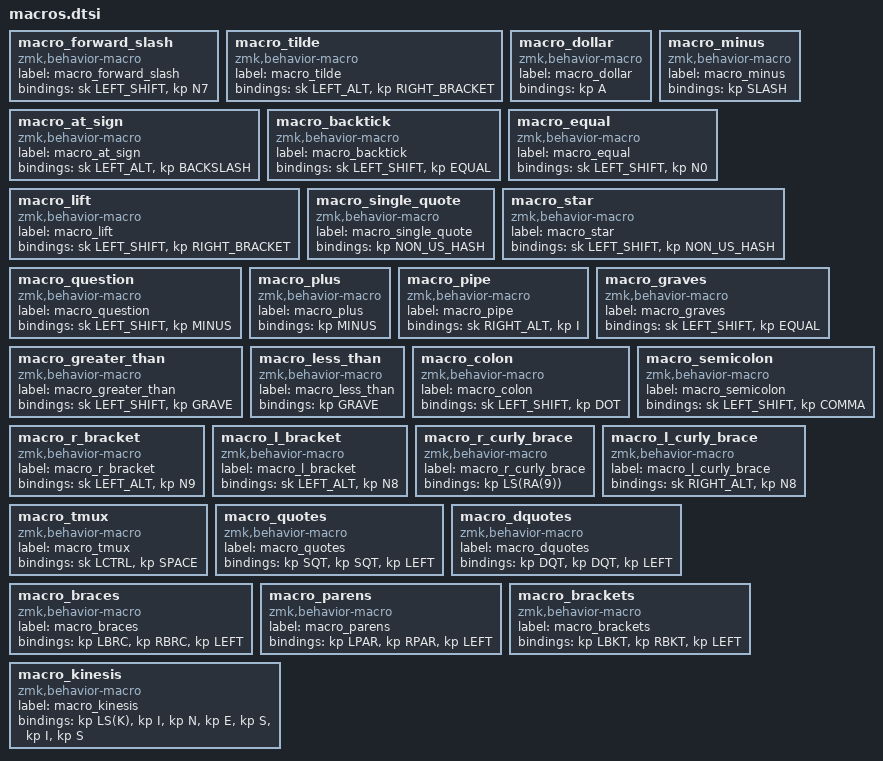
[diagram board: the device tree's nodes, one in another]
macro_forward_slash: macro_forward_slash{
compatible = "zmk,behavior-macro";
label = "macro_forward_slash";
#binding-cells = <0>;
bindings = <&sk LEFT_SHIFT>, <&kp N7>;
};
macro_tilde: macro_tilde{
compatible = "zmk,behavior-macro";
label = "macro_tilde";
#binding-cells = <0>;
bindings = <&sk LEFT_ALT>, <&kp RIGHT_BRACKET>;
};
macro_dollar: macro_dollar{
compatible = "zmk,behavior-macro";
label = "macro_dollar";
#binding-cells = <0>;
bindings = <&kp A>;
};
macro_minus: macro_minus{
compatible = "zmk,behavior-macro";
label = "macro_minus";
#binding-cells = <0>;
bindings = <&kp SLASH>;
};
macro_at_sign: macro_at_sign{
compatible = "zmk,behavior-macro";
label = "macro_at_sign";
#binding-cells = <0>;
bindings = <&sk LEFT_ALT>, <&kp BACKSLASH>;
};
macro_backtick: macro_backtick{
compatible = "zmk,behavior-macro";
label = "macro_backtick";
#binding-cells = <0>;
bindings = <&sk LEFT_SHIFT>, <&kp EQUAL>;
};
macro_equal: macro_equal{
compatible = "zmk,behavior-macro";
label = "macro_equal";
#binding-cells = <0>;
bindings = <&sk LEFT_SHIFT>, <&kp N0>;
};
macro_lift: macro_lift{
compatible = "zmk,behavior-macro";
label = "macro_lift";
#binding-cells = <0>;
bindings = <&sk LEFT_SHIFT>, <&kp RIGHT_BRACKET>;
};
macro_single_quote: macro_single_quote{
compatible = "zmk,behavior-macro";
label = "macro_single_quote";
#binding-cells = <0>;
bindings = <&kp NON_US_HASH>;
};
macro_star: macro_star{
compatible = "zmk,behavior-macro";
label = "macro_star";
#binding-cells = <0>;
bindings = <&sk LEFT_SHIFT>, <&kp NON_US_HASH>;
};
macro_question: macro_question{
compatible = "zmk,behavior-macro";
label = "macro_question";
#binding-cells = <0>;
bindings = <&sk LEFT_SHIFT>, <&kp MINUS>;
};
macro_plus: macro_plus{
compatible = "zmk,behavior-macro";
label = "macro_plus";
#binding-cells = <0>;
bindings = <&kp MINUS>;
};
macro_pipe: macro_pipe{
compatible = "zmk,behavior-macro";
label = "macro_pipe";
#binding-cells = <0>;
bindings = <&sk RIGHT_ALT>, <&kp I>;
};
macro_graves: macro_graves{
compatible = "zmk,behavior-macro";
label = "macro_graves";
#binding-cells = <0>;
bindings = <&sk LEFT_SHIFT>, <&kp EQUAL>;
};
macro_greater_than: macro_greater_than{
compatible = "zmk,behavior-macro";
label = "macro_greater_than";
#binding-cells = <0>;
bindings = <&sk LEFT_SHIFT>, <&kp GRAVE>;
};
macro_less_than: macro_less_than{
compatible = "zmk,behavior-macro";
label = "macro_less_than";
#binding-cells = <0>;
bindings = <&kp GRAVE>;
};
macro_colon: macro_colon{
compatible = "zmk,behavior-macro";
label = "macro_colon";
#binding-cells = <0>;
bindings = <&sk LEFT_SHIFT>, <&kp DOT>;
};
macro_semicolon: macro_semicolon{
compatible = "zmk,behavior-macro";
label = "macro_semicolon";
#binding-cells = <0>;
bindings = <&sk LEFT_SHIFT>, <&kp COMMA>;
};
macro_r_bracket: macro_r_bracket{
compatible = "zmk,behavior-macro";
label = "macro_r_bracket";
#binding-cells = <0>;
bindings = <&sk LEFT_ALT>, <&kp N9>;
};
macro_l_bracket: macro_l_bracket{
compatible = "zmk,behavior-macro";
label = "macro_l_bracket";
#binding-cells = <0>;
bindings = <&sk LEFT_ALT>, <&kp N8>;
};
macro_r_curly_brace: macro_r_curly_brace{
compatible = "zmk,behavior-macro";
label = "macro_r_curly_brace";
#binding-cells = <0>;
bindings = <&kp LS(RA(9))>;
};
macro_l_curly_brace: macro_l_curly_brace{
compatible = "zmk,behavior-macro";
label = "macro_l_curly_brace";
#binding-cells = <0>;
bindings = <&sk RIGHT_ALT>, <&kp N8>;
};
macro_tmux: macro_tmux{
compatible = "zmk,behavior-macro";
label = "macro_tmux";
#binding-cells = <0>;
bindings = <&sk LCTRL>, <&kp SPACE>;
};
macro_quotes: macro_quotes{
compatible = "zmk,behavior-macro";
label = "macro_quotes";
#binding-cells = <0>;
bindings = <&kp SQT>, <&kp SQT>, <&kp LEFT>;
};
macro_dquotes: macro_dquotes{
compatible = "zmk,behavior-macro";
label = "macro_dquotes";
#binding-cells = <0>;
bindings = <&kp DQT>, <&kp DQT>, <&kp LEFT>;
};
macro_braces: macro_braces{
compatible = "zmk,behavior-macro";
label = "macro_braces";
#binding-cells = <0>;
bindings = <&kp LBRC>, <&kp RBRC>, <&kp LEFT>;
};
macro_parens: macro_parens{
compatible = "zmk,behavior-macro";
label = "macro_parens";
#binding-cells = <0>;
bindings = <&kp LPAR>, <&kp RPAR>, <&kp LEFT>;
};
macro_brackets: macro_brackets{
compatible = "zmk,behavior-macro";
label = "macro_brackets";
#binding-cells = <0>;
bindings = <&kp LBKT>, <&kp RBKT>, <&kp LEFT>;
};
macro_kinesis: macro_kinesis{
compatible = "zmk,behavior-macro";
label = "macro_kinesis";
#binding-cells = <0>;
bindings = <&kp LS(K)>, <&kp I>, <&kp N>, <&kp E>, <&kp S>, <&kp I>, <&kp S>;
};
